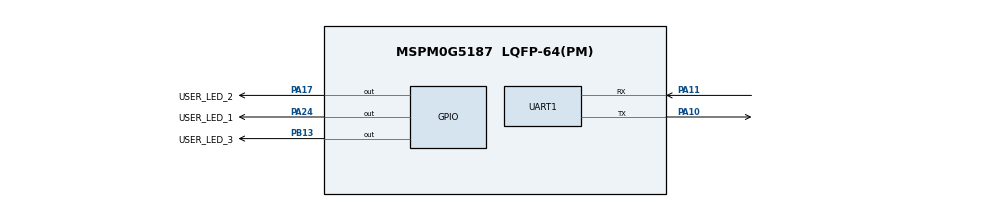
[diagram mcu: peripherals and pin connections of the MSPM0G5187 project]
//@cliArgs --device "MSPM0G518X" --package "LQFP-64(PM)" --part "Default"
//@v2CliArgs --device "MSPM0G5187" --package "LQFP-64(PM)"
// @cliArgs --board /ti/boards/LP_MSPM0G5187 --rtos nortos

/**
 * Import the modules used in this configuration.
 */
const ProjectConfig = scripting.addModule("/ti/project_config/ProjectConfig");
const Board         = scripting.addModule("/ti/driverlib/Board", {}, false);
const GPIO          = scripting.addModule("/ti/driverlib/GPIO", {}, false);
const GPIO1         = GPIO.addInstance();
const GPIO2         = GPIO.addInstance();
const UART          = scripting.addModule("/ti/driverlib/UART", {}, false);
const UART1         = UART.addInstance();
const SYSCTL        = scripting.addModule("/ti/driverlib/SYSCTL", {}, false);

/**
 * Write custom configuration values to the imported modules.
 */
ProjectConfig.genDisable = true;

/**
 * Write custom configuration values to the imported modules.
 */
GPIO1.$name                         = "GPIO_LEDS";
GPIO1.associatedPins.create(4);
GPIO1.associatedPins[0].$name       = "USER_LED_1";
GPIO1.associatedPins[0].pin.$assign = "PA24";
GPIO1.associatedPins[1].$name       = "USER_LED_2";
GPIO1.associatedPins[1].pin.$assign = "PA17";
GPIO1.associatedPins[2].$name       = "USER_LED_3";
GPIO1.associatedPins[2].pin.$assign = "PB13";

GPIO2.$name                              = "GPIO_SWITCHES";
GPIO2.associatedPins[0].assignedPort     = "PORTA";
GPIO2.associatedPins[0].$name            = "USER_SWITCH_1";
GPIO2.associatedPins[0].direction        = "INPUT";
GPIO2.associatedPins[0].interruptEn      = true;
GPIO2.associatedPins[0].polarity         = "RISE";
GPIO2.associatedPins[0].assignedPin      = "7";
GPIO2.associatedPins[0].internalResistor = "PULL_UP";

UART1.$name                    = "UART_0";
UART1.targetBaudRate           =  9600;
UART1.peripheral.$assign       = "UC0";
UART1.peripheral.rxPin.$assign = "PA11";
UART1.peripheral.txPin.$assign = "PA10";
